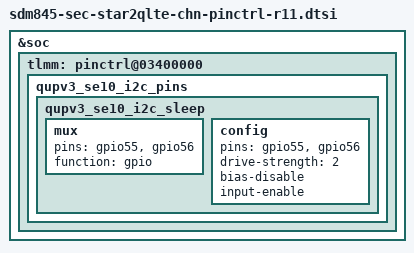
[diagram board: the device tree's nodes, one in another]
/* Copyright (c) 2016-2017, The Linux Foundation. All rights reserved.
 *
 * This program is free software; you can redistribute it and/or modify
 * it under the terms of the GNU General Public License version 2 and
 * only version 2 as published by the Free Software Foundation.
 *
 * This program is distributed in the hope that it will be useful,
 * but WITHOUT ANY WARRANTY; without even the implied warranty of
 * MERCHANTABILITY or FITNESS FOR A PARTICULAR PURPOSE.  See the
 * GNU General Public License for more details.
 */

#include "sdm845-sec-star2qlte-chn-pinctrl-r10.dtsi"

&soc {
	tlmm: pinctrl@03400000 {
		qupv3_se10_i2c_pins: qupv3_se10_i2c_pins {
			/delete-node/ qupv3_se10_i2c_sleep;
			qupv3_se10_i2c_sleep: qupv3_se10_i2c_sleep {
				mux {
					pins = "gpio55", "gpio56";
					function = "gpio";
				};

				config {
					pins = "gpio55", "gpio56";
					drive-strength = <2>;
					bias-disable;
					input-enable;
				};
			};
		};
	};
};
